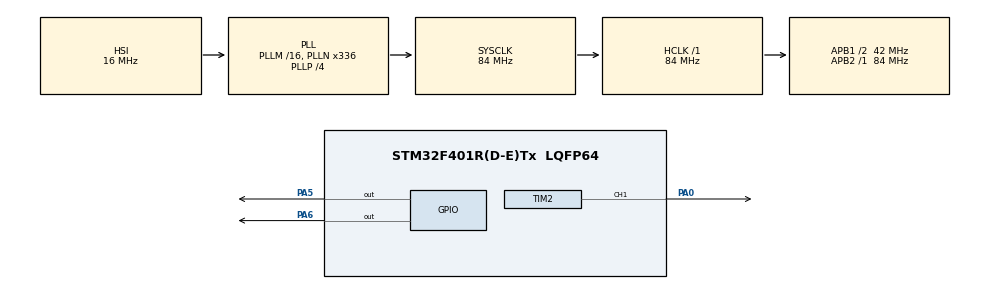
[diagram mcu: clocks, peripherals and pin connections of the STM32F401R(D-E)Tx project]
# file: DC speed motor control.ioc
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Mcu.Family=STM32F4
Mcu.Name=STM32F401R(D-E)Tx
Mcu.Package=LQFP64
NVIC.PriorityGroup=NVIC_PRIORITYGROUP_4
PA0-WKUP.Signal=S_TIM2_CH1_ETR
PA5.Signal=GPIO_Output
PA6.Signal=GPIO_Output
ProjectManager.HeapSize=0x200
ProjectManager.StackSize=0x400
ProjectManager.TargetToolchain=STM32CubeIDE
RCC.48MHZClocksFreq_Value=48000000
RCC.AHBFreq_Value=84000000
RCC.APB1CLKDivider=RCC_HCLK_DIV2
RCC.APB1Freq_Value=42000000
RCC.APB1TimFreq_Value=84000000
RCC.APB2Freq_Value=84000000
RCC.APB2TimFreq_Value=84000000
RCC.CortexFreq_Value=84000000
RCC.HCLKFreq_Value=84000000
RCC.HSE_VALUE=8000000
RCC.HSI_VALUE=16000000
RCC.PLLN=336
RCC.PLLP=RCC_PLLP_DIV4
RCC.PLLQ=7
RCC.SYSCLKFreq_VALUE=84000000
RCC.SYSCLKSource=RCC_SYSCLKSOURCE_PLLCLK
RCC.VCOOutputFreq_Value=336000000
SH.S_TIM2_CH1_ETR.0=TIM2_CH1,PWM Generation1 CH1
TIM2.Channel-PWM\ Generation1\ CH1=TIM_CHANNEL_1
TIM2.Period=999
TIM2.Prescaler=83
VP_TIM2_VS_ClockSourceINT.Mode=Internal
board=NUCLEO-F401RE

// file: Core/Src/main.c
/* USER CODE BEGIN Header */
/**
  ******************************************************************************
  * @file           : main.c
  * @brief          : Main program body
  ******************************************************************************
  * @attention
  *
  * Copyright (c) 2026 STMicroelectronics.
  * All rights reserved.
  *
  * This software is licensed under terms that can be found in the LICENSE file
  * in the root directory of this software component.
  * If no LICENSE file comes with this software, it is provided AS-IS.
  *
  ******************************************************************************
  */
/* USER CODE END Header */
#include "main.h"

TIM_HandleTypeDef htim2;

void SystemClock_Config(void);
static void MX_GPIO_Init(void);
static void MX_TIM2_Init(void);

/* USER CODE BEGIN 0 */

uint32_t adc_val = 0;
uint32_t pwm_val = 0;
/* USER CODE END 0 */

int main(void)
{

  /* MCU Configuration--------------------------------------------------------*/

  /* Reset of all peripherals, Initializes the Flash interface and the Systick. */
  HAL_Init();

  /* Configure the system clock */
  SystemClock_Config();

  /* Initialize all configured peripherals */
  MX_GPIO_Init();
  MX_TIM2_Init();
  /* USER CODE BEGIN 2 */
 // HAL_ADC_Start(&hadc1);

  HAL_TIM_PWM_Start(&htim2, TIM_CHANNEL_1);
  /* USER CODE END 2 */

  /* Infinite loop */
  while (1)
  {

    /* USER CODE BEGIN 3 */

	  HAL_GPIO_WritePin(GPIOB, GPIO_PIN_0, GPIO_PIN_SET);   // IN1 HIGH
	     HAL_GPIO_WritePin(GPIOB, GPIO_PIN_1, GPIO_PIN_RESET);

	     // 25% speed
	           __HAL_TIM_SET_COMPARE(&htim2, TIM_CHANNEL_1, 250);

	           // 50% speed
	           __HAL_TIM_SET_COMPARE(&htim2, TIM_CHANNEL_1, 500);

	           // 75% speed
	           __HAL_TIM_SET_COMPARE(&htim2, TIM_CHANNEL_1, 750);

	           // 100% speed
	           __HAL_TIM_SET_COMPARE(&htim2, TIM_CHANNEL_1, 1000);

  }
  /* USER CODE END 3 */
}

void SystemClock_Config(void)
{
  RCC_OscInitTypeDef RCC_OscInitStruct = {0};
  RCC_ClkInitTypeDef RCC_ClkInitStruct = {0};

  /** Configure the main internal regulator output voltage
  */
  __HAL_RCC_PWR_CLK_ENABLE();
  __HAL_PWR_VOLTAGESCALING_CONFIG(PWR_REGULATOR_VOLTAGE_SCALE2);

  /** Initializes the RCC Oscillators according to the specified parameters
  * in the RCC_OscInitTypeDef structure.
  */
  RCC_OscInitStruct.OscillatorType = RCC_OSCILLATORTYPE_HSI;
  RCC_OscInitStruct.HSIState = RCC_HSI_ON;
  RCC_OscInitStruct.HSICalibrationValue = RCC_HSICALIBRATION_DEFAULT;
  RCC_OscInitStruct.PLL.PLLState = RCC_PLL_ON;
  RCC_OscInitStruct.PLL.PLLSource = RCC_PLLSOURCE_HSI;
  RCC_OscInitStruct.PLL.PLLM = 16;
  RCC_OscInitStruct.PLL.PLLN = 336;
  RCC_OscInitStruct.PLL.PLLP = RCC_PLLP_DIV4;
  RCC_OscInitStruct.PLL.PLLQ = 7;
  if (HAL_RCC_OscConfig(&RCC_OscInitStruct) != HAL_OK)
  {
    Error_Handler();
  }

  /** Initializes the CPU, AHB and APB buses clocks
  */
  RCC_ClkInitStruct.ClockType = RCC_CLOCKTYPE_HCLK|RCC_CLOCKTYPE_SYSCLK
                              |RCC_CLOCKTYPE_PCLK1|RCC_CLOCKTYPE_PCLK2;
  RCC_ClkInitStruct.SYSCLKSource = RCC_SYSCLKSOURCE_PLLCLK;
  RCC_ClkInitStruct.AHBCLKDivider = RCC_SYSCLK_DIV1;
  RCC_ClkInitStruct.APB1CLKDivider = RCC_HCLK_DIV2;
  RCC_ClkInitStruct.APB2CLKDivider = RCC_HCLK_DIV1;

  if (HAL_RCC_ClockConfig(&RCC_ClkInitStruct, FLASH_LATENCY_2) != HAL_OK)
  {
    Error_Handler();
  }
}

static void MX_TIM2_Init(void)
{

  TIM_ClockConfigTypeDef sClockSourceConfig = {0};
  TIM_MasterConfigTypeDef sMasterConfig = {0};
  TIM_OC_InitTypeDef sConfigOC = {0};

  htim2.Instance = TIM2;
  htim2.Init.Prescaler = 83;
  htim2.Init.CounterMode = TIM_COUNTERMODE_UP;
  htim2.Init.Period = 999;
  htim2.Init.ClockDivision = TIM_CLOCKDIVISION_DIV1;
  htim2.Init.AutoReloadPreload = TIM_AUTORELOAD_PRELOAD_DISABLE;
  if (HAL_TIM_Base_Init(&htim2) != HAL_OK)
  {
    Error_Handler();
  }
  sClockSourceConfig.ClockSource = TIM_CLOCKSOURCE_INTERNAL;
  if (HAL_TIM_ConfigClockSource(&htim2, &sClockSourceConfig) != HAL_OK)
  {
    Error_Handler();
  }
  if (HAL_TIM_PWM_Init(&htim2) != HAL_OK)
  {
    Error_Handler();
  }
  sMasterConfig.MasterOutputTrigger = TIM_TRGO_RESET;
  sMasterConfig.MasterSlaveMode = TIM_MASTERSLAVEMODE_DISABLE;
  if (HAL_TIMEx_MasterConfigSynchronization(&htim2, &sMasterConfig) != HAL_OK)
  {
    Error_Handler();
  }
  sConfigOC.OCMode = TIM_OCMODE_PWM1;
  sConfigOC.Pulse = 0;
  sConfigOC.OCPolarity = TIM_OCPOLARITY_HIGH;
  sConfigOC.OCFastMode = TIM_OCFAST_DISABLE;
  if (HAL_TIM_PWM_ConfigChannel(&htim2, &sConfigOC, TIM_CHANNEL_1) != HAL_OK)
  {
    Error_Handler();
  }
  HAL_TIM_MspPostInit(&htim2);

}

static void MX_GPIO_Init(void)
{
  GPIO_InitTypeDef GPIO_InitStruct = {0};

  /* GPIO Ports Clock Enable */
  __HAL_RCC_GPIOA_CLK_ENABLE();

  /*Configure GPIO pin Output Level */
  HAL_GPIO_WritePin(GPIOA, GPIO_PIN_5|GPIO_PIN_6, GPIO_PIN_RESET);

  /*Configure GPIO pins : PA5 PA6 */
  GPIO_InitStruct.Pin = GPIO_PIN_5|GPIO_PIN_6;
  GPIO_InitStruct.Mode = GPIO_MODE_OUTPUT_PP;
  GPIO_InitStruct.Pull = GPIO_NOPULL;
  GPIO_InitStruct.Speed = GPIO_SPEED_FREQ_LOW;
  HAL_GPIO_Init(GPIOA, &GPIO_InitStruct);

}

void Error_Handler(void)
{
  __disable_irq();
  while (1)
  {
  }
}
